# RA register map
Vendor: Renesas; Series: All Chips; File version: x.xx
Registers are 32-bit, read-write, reset 0x0 unless marked. A register's access mark holds for its fields unless they carry their own. Offsets are from the block's base; [hi:lo] are bit positions; lines under a group give offsets from that group; {n}, {i} and the like mark numbered series; 'fields as' and 'values as' point back to an identical list.

## R_BUS — Bus Interface
Base 0x40003000
{0x0+0x10*i} CSa[{i}] (i=0..7) group — CS Registers
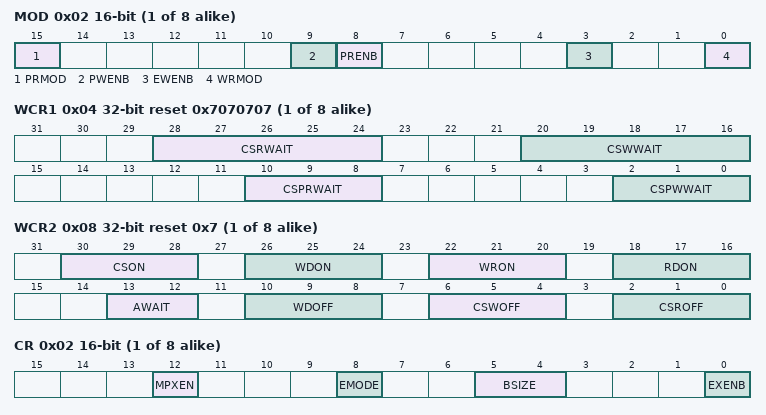
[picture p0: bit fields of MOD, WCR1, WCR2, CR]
  0x02 MOD 16-bit — Mode Register
    [15] PRMOD — Page Read Access Mode Select
      0=Normal access compatible mode; 1=External data read continuous assertion mode
    [9] PWENB — Page Write Access Enable
      0=Disable; 1=Enable
    [8] PRENB — Page Read Access Enable
      0=Disable; 1=Enable
    [3] EWENB — External Wait Enable
      0=Disable; 1=Enable
    [0] WRMOD — Write Access Mode Select
      0=Byte strobe mode; 1=Single write strobe mode
  0x04 WCR1 reset 0x7070707 — Wait Control Register 1
    [28:24] CSRWAIT — Normal Read Cycle Wait Select
      0=No wait is inserted; other=others (Wait with a length of CSRWAIT clock cycle is inserted.)
    [20:16] CSWWAIT — Normal Write Cycle Wait Select
      0=No wait is inserted; other=others (Wait with a length of CSWWAIT clock cycle is inserted.)
    [10:8] CSPRWAIT — Page Read Cycle Wait SelectNOTE: The CSPRWAIT value is valid only when the PRENB bit in CSnMOD is set to 1.
      0=No wait is inserted; other=others (Wait with a length of CSPRWAIT clock cycle is inserted.)
    [2:0] CSPWWAIT — Page Write Cycle Wait SelectNOTE: The CSPWWAIT value is valid only when the PWENB bit in CSnMOD is set to 1.
      0=No wait is inserted; other=others (Wait with a length of CSPWWAIT clock cycle is inserted.)
  0x08 WCR2 reset 0x7 — Wait Control Register 2
    [30:28] CSON — CS Assert Wait Select
      0=No wait is inserted; other=others (Wait with a length of CSON clock cycle is inserted.)
    [26:24] WDON — Write Data Output Wait Select
      0=No wait is inserted; other=others (Wait with a length of WDON clock cycle is inserted.)
    [22:20] WRON — WR Assert Wait Select
      0=No wait is inserted; other=others (Wait with a length of WRON clock cycle is inserted.)
    [18:16] RDON — RD Assert Wait Select
      0=No wait is inserted; other=others (Wait with a length of RDON clock cycle is inserted.)
    [13:12] AWAIT — CS Assert Wait Select
      0=No wait is inserted; other=others (Wait with a length of AWAIT clock cycle is inserted.)
    [10:8] WDOFF — Write Data Output Extension Cycle Select
      0=No wait is inserted; other=others (Wait with a length of WDOFF clock cycle is inserted.)
    [6:4] CSWOFF — Write-Access CS Extension Cycle Select
      0=No wait is inserted; other=others (Wait with a length of CSWOFF clock cycle is inserted.)
    [2:0] CSROFF — Read-Access CS Extension Cycle Select
      0=No wait is inserted; other=others (Wait with a length of CSROFF clock cycle is inserted.)
{0x800+0x10*i} CSb[{i}] (i=0..7) group — CS Registers
  0x02 CR 16-bit — Control Register
    [12] MPXEN — Address/Data Multiplexed I/O Interface Select
      0=Separate bus interface is selected for area n; 1=Address/data multiplexed I/O interface is selected for area n. (n = 0 to 7)
    [8] EMODE — Endian Mode
      0=Little Endian; 1=Big Endian
    [5:4] BSIZE — External Bus Width Select
      0=A 16-bit bus space; 1=Setting prohibited; 2=An 8-bit bus space; 3=Setting prohibited
    [0] EXENB — Operation Enable
      0=Disable operation; 1=Enable operation
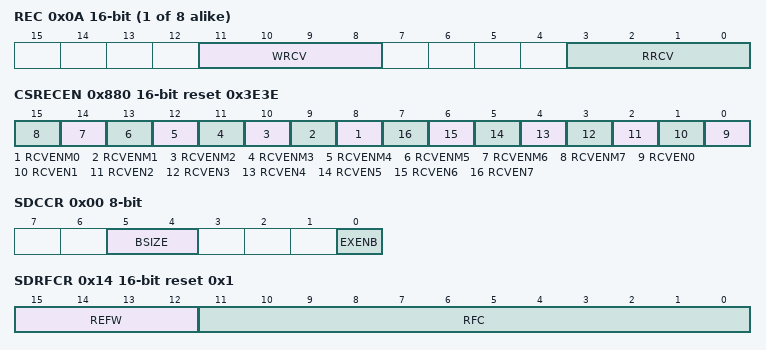
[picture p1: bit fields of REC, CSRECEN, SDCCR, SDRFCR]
  0x0A REC 16-bit — Recovery Cycle Register
    [11:8] WRCV — Write Recovery
      0=No recovery cycle is inserted; other=others (WRCV recovery cycle is inserted.)
    [3:0] RRCV — Read Recovery
      0=No recovery cycle is inserted; other=others (RRCV recovery cycle is inserted.)
0x880 CSRECEN 16-bit reset 0x3E3E — CS Recovery Cycle Insertion Enable Register
  [n+8] RCVENM{n} (n=0..7) — Multiplexed Bus Recovery Cycle Insertion Enable
    0=Recovery cycle insertion is disabled; 1=Recovery cycle insertion is enabled
  [n] RCVEN{n} (n=0..7) — Separate Bus Recovery Cycle Insertion Enable
    values as RCVENM0
0xC00 SDRAM group — SDRAM Registers
  0x00 SDCCR 8-bit — SDC Control Register
    [5:4] BSIZE — SDRAM Bus Width Select
      values as CSb[0].CR.BSIZE
    [0] EXENB — Operation Enable
      0=Disable; 1=Enable
  0x01 SDCMOD 8-bit — SDC Mode Register
    [0] EMODE — Endian Mode
      0=Endian order of SDRAM address space is the same as the endian order of the operating mode; 1=Endian order of SDRAM address space is not the endian order of the operating mode
  0x02 SDAMOD 8-bit — SDRAM Access Mode Register
    [0] BE — Continuous Access Enable
      0=Disable; 1=Enable
  0x10 SDSELF 8-bit — SDRAM Self-Refresh Control Register
    [0] SFEN — SDRAM Self-Refresh Enable
      0=Disable; 1=Enable
  0x14 SDRFCR 16-bit reset 0x1 — SDRAM Refresh Control Register
    [15:12] REFW — Auto-Refresh Cycle/ Self-Refresh Clearing Cycle Count Setting. ( REFW+1 Cycles )
    [11:0] RFC — Auto-Refresh Request Interval Setting
      0=Setting prohibited; other=others (RFC+1 cycles inserted)
  0x16 SDRFEN 8-bit — SDRAM Auto-Refresh Control Register
    [0] RFEN — Auto-Refresh Operation Enable
      0=Disable; 1=Enable
  0x20 SDICR 8-bit — SDRAM Initialization Sequence Control Register
    [0] INIRQ — Initialization Sequence Start
      0=Invalid; 1=Initialization sequence starts
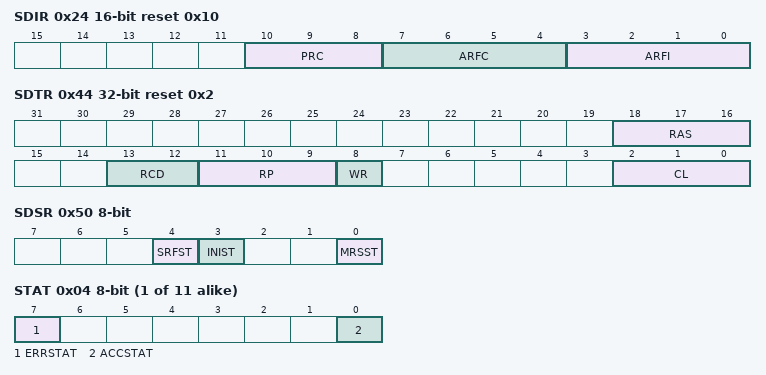
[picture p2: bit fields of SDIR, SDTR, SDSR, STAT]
  0x24 SDIR 16-bit reset 0x10 — SDRAM Initialization Register
    [10:8] PRC — Initialization Precharge Cycle Count ( PRF+3 cycles )
    [7:4] ARFC — Initialization Auto-Refresh Count
      0=Setting prohibited; other=others (ARFC+1 times)
    [3:0] ARFI — Initialization Auto-Refresh Interval ( PRF+3 cycles )
  0x40 SDADR 8-bit — SDRAM Address Register
    [1:0] MXC — Address Multiplex Select
      {v}={v+8}-bit shift (v=0..3)
  0x44 SDTR reset 0x2 — SDRAM Timing Register
    [18:16] RAS — Row Active Interval
      0=1 cycle; {v}={v+1} cycles (v=1..6); 7=Setting prohibited
    [13:12] RCD — Row Column Latency ( RCD+1 cycles )
    [11:9] RP — Row Precharge Interval ( RP+1 cycles )
    [8] WR — Write Recovery Interval
      0=1 cycle; 1=2 cycles
    [2:0] CL — SDRAMC Column Latency
      1=1 cycle; 2=2 cycles; 3=3 cycles; other=others (Setting prohibited)
  0x48 SDMOD 16-bit — SDRAM Mode Register
    [14:0] MR — Mode Register SettingWriting to these bits: Mode register set command is issued.
  0x50 SDSR 8-bit ro — SDRAM Status Register
    [4] SRFST — Self-Refresh Transition/Recovery Status
      0=Transition/recovery not in progress; 1=Transition/recovery in progress
    [3] INIST — Initialization Status
      0=Initialization sequence not in progress; 1=Initialization sequence in progress
    [0] MRSST — Mode Register Setting Status
      0=Mode register setting not in progress; 1=Mode register setting in progress
{0x1000+4i} BUSM[{i}] (i=0..5) group — Master Bus Control Register Array
  0x00 CNT 16-bit — Master Bus Control Register
    [15] IERES — Ignore Error Responses
      0=Bus error will be reported; 1=Bus error will not be reported
{0x1100+4i} BUSS[{i}] (i=0..15) group — Slave Bus Control Register Array
  0x00 CNT 16-bit — Slave Bus Control Register
    [5:4] ARBMET — Arbitration MethodSpecify the priority between groups
      0=fixed priority; 1=round-robin; other=others (Setting prohibited)
{0x1800+0x10*i} BUSERR[{i}] (i=0..10) group — Bus Error Registers
  0x00 ADD ro reset not defined — Bus Error Address Register
    [31:0] BERAD — Bus Error AddressWhen a bus error occurs, It stores an error address.
  0x04 STAT 8-bit ro (reset mask 0xFE) — Bus Error Status Register
    [7] ERRSTAT — Bus Error StatusWhen bus error assert, error flag occurs.
      0=No bus error occurred; 1=Bus error occurred
    [0] ACCSTAT — Error access statusThe status at the time of the error
      0=Read access; 1=Write Access
